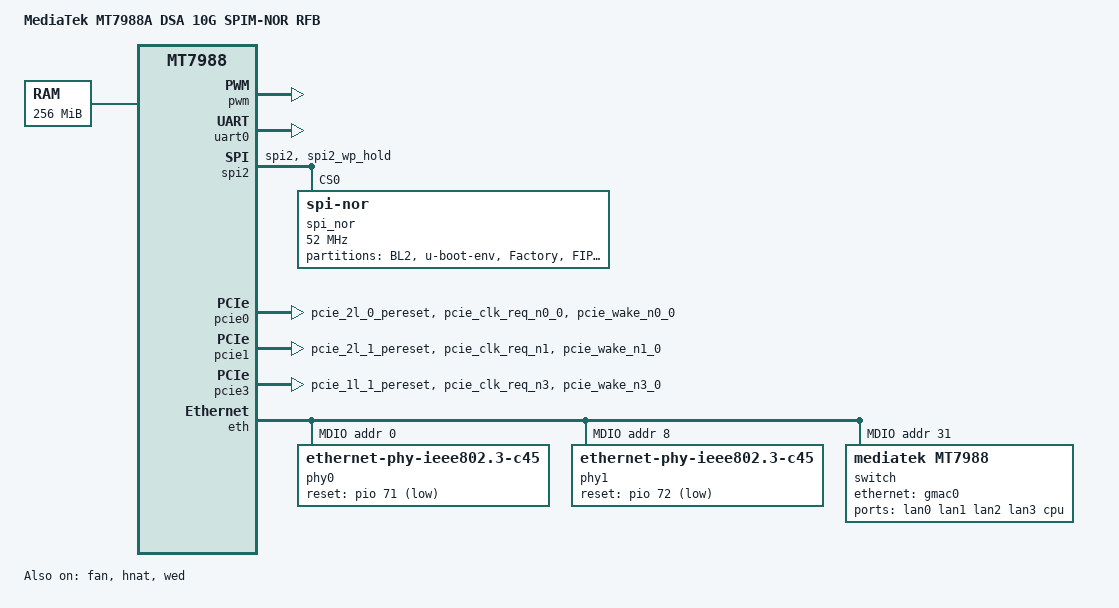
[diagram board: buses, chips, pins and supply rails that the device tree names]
// SPDX-License-Identifier: (GPL-2.0 OR MIT)
/*
 * Copyright (C) 2021 MediaTek Inc.
 * Author: Sam.Shih <sam.shih@mediatek.com>
 */

/dts-v1/;
#include "mt7988.dtsi"

/ {
	model = "MediaTek MT7988A DSA 10G SPIM-NOR RFB";
	compatible = "mediatek,mt7988a-dsa-10g-spim-nor",
		     /* Reserve this for DVFS if creating new dts */
		     "mediatek,mt7988";

	chosen {
		bootargs = "console=ttyS0,115200n1 loglevel=8  \
			    earlycon=uart8250,mmio32,0x11000000 \
			    pci=pcie_bus_perf";
	};

	memory {
		reg = <0 0x40000000 0 0x10000000>;
	};

	wsys_adie: wsys_adie@0 {
	// fpga cases need to manual change adie_id / sku_type for dvt only
		compatible = "mediatek,rebb-mt7988-adie";
		adie_id = <7976>;
		sku_type = <3000>;
	};
};

&fan {
	pwms = <&pwm 0 50000 0>;
	status = "okay";
};

&pwm {
	status = "okay";
};

&uart0 {
	status = "okay";
};

&spi1 {
	pinctrl-names = "default";
	/* pin shared with snfi */
	pinctrl-0 = <&spic_pins>;
	status = "disabled";
};

&spi2 {
	pinctrl-names = "default";
	pinctrl-0 = <&spi2_flash_pins>;
	status = "okay";
	spi_nor@0 {
		#address-cells = <1>;
		#size-cells = <1>;
		compatible = "jedec,spi-nor";
		spi-cal-enable;
		spi-cal-mode = "read-data";
		spi-cal-datalen = <7>;
		spi-cal-data = /bits/ 8 <
			0x53 0x46 0x5F 0x42 0x4F 0x4F 0x54>; /* SF_BOOT */
		spi-cal-addrlen = <1>;
		spi-cal-addr = /bits/ 32 <0x0>;
		reg = <0>;
		spi-max-frequency = <52000000>;

		partition@00000 {
			label = "BL2";
			reg = <0x00000 0x0040000>;
		};
		partition@40000 {
			label = "u-boot-env";
			reg = <0x40000 0x0010000>;
		};
		factory: partition@50000 {
			label = "Factory";
			reg = <0x50000 0x00B0000>;
		};
		partition@100000 {
			label = "FIP";
			reg = <0x100000 0x0080000>;
		};
		partition@180000 {
			label = "firmware";
			reg = <0x180000 0xE00000>;
		};
	};
};

&pcie0 {
	pinctrl-names = "default";
	pinctrl-0 = <&pcie0_pins>;
	status = "okay";
};

&pcie1 {
	pinctrl-names = "default";
	pinctrl-0 = <&pcie1_pins>;
	status = "okay";
};

&pcie2 {
	pinctrl-names = "default";
	pinctrl-0 = <&pcie2_pins>;
	status = "disabled";
};

&pcie3 {
	pinctrl-names = "default";
	pinctrl-0 = <&pcie3_pins>;
	status = "okay";
};

&pio {
	pcie0_pins: pcie0-pins {
		mux {
			function = "pcie";
			groups = "pcie_2l_0_pereset", "pcie_clk_req_n0_0",
				 "pcie_wake_n0_0";
		};
	};

	pcie1_pins: pcie1-pins {
		mux {
			function = "pcie";
			groups = "pcie_2l_1_pereset", "pcie_clk_req_n1",
				 "pcie_wake_n1_0";
		};
	};

	pcie2_pins: pcie2-pins {
		mux {
			function = "pcie";
			groups = "pcie_1l_0_pereset", "pcie_clk_req_n2_0",
				 "pcie_wake_n2_0";
		};
	};

	pcie3_pins: pcie3-pins {
		mux {
			function = "pcie";
			groups = "pcie_1l_1_pereset", "pcie_clk_req_n3",
				 "pcie_wake_n3_0";
		};
	};

	spic_pins: spi1-pins {
		mux {
			function = "spi";
			groups = "spi1_1";
		};
	};

	spi2_flash_pins: spi2-pins {
		mux {
			function = "spi";
			groups = "spi2", "spi2_wp_hold";
		};
	};
};

&watchdog {
	status = "disabled";
};

&eth {
	status = "okay";

	gmac0: mac@0 {
		compatible = "mediatek,eth-mac";
		reg = <0>;
		phy-mode = "10gbase-kr";

		fixed-link {
			speed = <2500>;
			full-duplex;
			pause;
		};
	};

	gmac1: mac@1 {
		compatible = "mediatek,eth-mac";
		reg = <1>;
		phy-mode = "10gbase-kr";
		phy-handle = <&phy0>;
	};

	gmac2: mac@2 {
		compatible = "mediatek,eth-mac";
		reg = <2>;
		phy-mode = "10gbase-kr";
		phy-handle = <&phy1>;
	};

	mdio: mdio-bus {
		#address-cells = <1>;
		#size-cells = <0>;
		phy0: ethernet-phy@0 {
			reg = <0>;
			compatible = "ethernet-phy-ieee802.3-c45";
			reset-gpios = <&pio 71 1>;
			reset-assert-us = <1000000>;
			reset-deassert-us = <1000000>;
		};

		phy1: ethernet-phy@8 {
			reg = <8>;
			compatible = "ethernet-phy-ieee802.3-c45";
			reset-gpios = <&pio 72 1>;
			reset-assert-us = <1000000>;
			reset-deassert-us = <1000000>;
		};

		switch@0 {
			compatible = "mediatek,mt7988";
			reg = <31>;
			ports {
				#address-cells = <1>;
				#size-cells = <0>;

				port@0 {
					reg = <0>;
					label = "lan0";
				};

				port@1 {
					reg = <1>;
					label = "lan1";
				};

				port@2 {
					reg = <2>;
					label = "lan2";
				};

				port@3 {
					reg = <3>;
					label = "lan3";
				};

				port@6 {
					reg = <6>;
					label = "cpu";
					ethernet = <&gmac0>;
					phy-mode = "10gbase-kr";

					fixed-link {
						speed = <10000>;
						full-duplex;
						pause;
					};
				};
			};
		};
	};
};

&hnat {
	mtketh-wan = "eth1";
	mtketh-lan = "lan";
	mtketh-lan2 = "eth2";
	mtketh-max-gmac = <3>;
	status = "okay";
};

&wed {
	dy_txbm_enable = "true";
	dy_txbm_budge = <8>;
	txbm_init_sz = <10>;
	status = "okay";
};
